VERSION ""

NS_ :

BS_:

BU_:

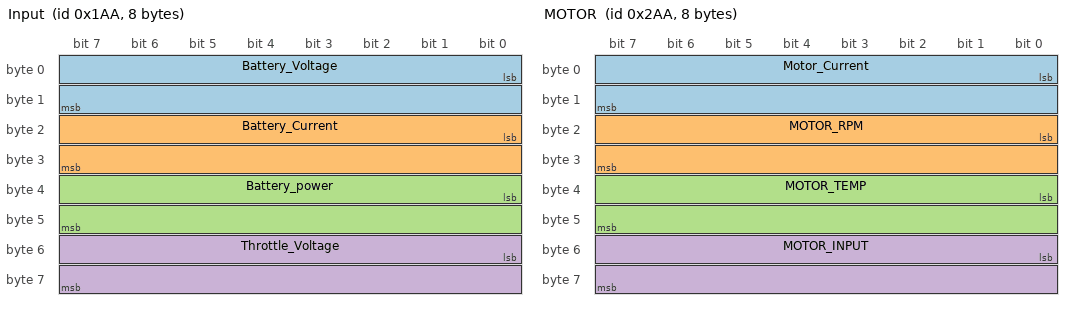
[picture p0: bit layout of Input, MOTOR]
BO_ 426 Input: 8 Vector__XXX
	SG_ Battery_Voltage : 0|16@1+ (0.032,-1.2) [-3276.7|3276.7] "Volts" Vector__XXX
	SG_ Battery_Current : 16|16@1- (0.032,0) [-3276.7|3276.7] "Amperes" Vector__XXX
	SG_ Battery_power : 32|16@1- (1,0) [-3276.7|3276.7] "Watts " Vector__XXX
	SG_ Throttle_Voltage : 48|16@1+ (0.000244140625,0) [-3276.7|3276.7] "Volts" Vector__XXX

BO_ 682 MOTOR: 8 Vector__XXX
	SG_ Motor_Current : 0|16@1- (0.032,0) [-3276.7|3276.7] "Amps" Vector__XXX
	SG_ MOTOR_RPM : 16|16@1- (1,0) [-3276.7|3276.7] "RPM" Vector__XXX
	SG_ MOTOR_TEMP : 32|16@1- (1,0) [-25|255] "Degree Celsius" Vector__XXX
	SG_ MOTOR_INPUT : 48|16@1- (1,0) [-3276.7|3276.7] "Amps" Vector__XXX

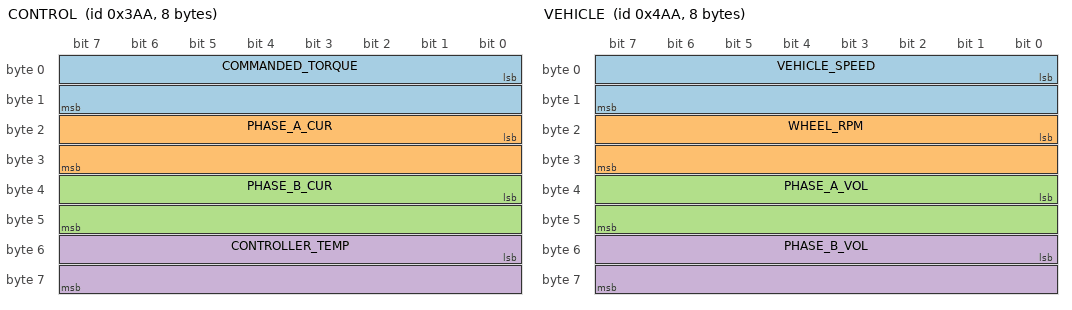
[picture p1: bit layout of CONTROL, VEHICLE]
BO_ 938 CONTROL: 8 Vector__XXX
	SG_ COMMANDED_TORQUE : 0|16@1+ (0.0244140625,0) [0|100] "%" Vector__XXX
	SG_ PHASE_A_CUR : 16|16@1- (0.032,0) [-3276.7|65535] "Amps" Vector__XXX
	SG_ PHASE_B_CUR : 32|16@1- (0.032,0) [-3276.7|3276.7] "Amps" Vector__XXX
	SG_ CONTROLLER_TEMP : 48|16@1- (1,0) [-25|255] "Degree Celsius" Vector__XXX

BO_ 1194 VEHICLE: 8 Vector__XXX
	SG_ VEHICLE_SPEED : 0|16@1+ (0.00390625,0) [0|65535] "KMPH" Vector__XXX
	SG_ WHEEL_RPM : 16|16@1+ (0.0625,0) [0|65535] "RPM" Vector__XXX
	SG_ PHASE_A_VOL : 32|16@1- (0.032,0) [-3276.7|3276.7] "Volts" Vector__XXX
	SG_ PHASE_B_VOL : 48|16@1- (0.032,0) [-3276.7|3276.7] "volts" Vector__XXX

CM_ BO_ 426 "INPUT PARAMETERS";
CM_ SG_ 426 Battery_Voltage "Voltage reading of the battery";
CM_ BO_ 682 "MOTOR PARAMETERS";
CM_ SG_ 682 Motor_Current "Motor Phase current ";
CM_ BO_ 938 "CONTOLLER PARAMETERS";
CM_ BO_ 1194 "VEHICLE PARAMETERS";
BA_DEF_ SG_  "SPN" INT 0 524287;
BA_DEF_ BO_  "VFrameFormat" ENUM  "StandardCAN","ExtendedCAN","reserved","J1939PG";
BA_DEF_  "DatabaseVersion" STRING ;
BA_DEF_  "BusType" STRING ;
BA_DEF_  "ProtocolType" STRING ;
BA_DEF_  "DatabaseCompiler" STRING ;
BA_DEF_DEF_  "SPN" 0;
BA_DEF_DEF_  "VFrameFormat" "J1939PG";
BA_DEF_DEF_  "DatabaseVersion" "DEMO PLUS";
BA_DEF_DEF_  "BusType" "";
BA_DEF_DEF_  "ProtocolType" "";
BA_DEF_DEF_  "DatabaseCompiler" "";
BA_ "ProtocolType" "J1939";
BA_ "BusType" "CAN";
BA_ "DatabaseCompiler" "CSS ELECTRONICS (WWW.CSSELECTRONICS.COM)";
BA_ "DatabaseVersion" "1.0.0";
BA_ "SPN" SG_ 2364540158 EngineSpeed 190;
BA_ "SPN" SG_ 2566844926 WheelBasedVehicleSpeed 84;
